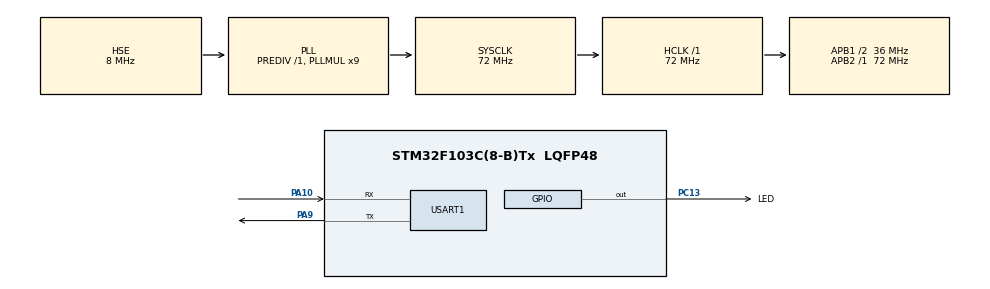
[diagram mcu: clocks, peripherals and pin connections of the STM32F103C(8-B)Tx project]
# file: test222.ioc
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Dma.Request0=USART1_TX
Dma.Request1=USART1_RX
Dma.USART1_RX.1.Direction=DMA_PERIPH_TO_MEMORY
Dma.USART1_RX.1.Instance=DMA1_Channel5
Dma.USART1_RX.1.MemDataAlignment=DMA_MDATAALIGN_BYTE
Dma.USART1_RX.1.MemInc=DMA_MINC_ENABLE
Dma.USART1_RX.1.Mode=DMA_NORMAL
Dma.USART1_RX.1.PeriphDataAlignment=DMA_PDATAALIGN_BYTE
Dma.USART1_RX.1.PeriphInc=DMA_PINC_DISABLE
Dma.USART1_RX.1.Priority=DMA_PRIORITY_LOW
Dma.USART1_TX.0.Direction=DMA_MEMORY_TO_PERIPH
Dma.USART1_TX.0.Instance=DMA1_Channel4
Dma.USART1_TX.0.MemDataAlignment=DMA_MDATAALIGN_BYTE
Dma.USART1_TX.0.MemInc=DMA_MINC_ENABLE
Dma.USART1_TX.0.Mode=DMA_NORMAL
Dma.USART1_TX.0.PeriphDataAlignment=DMA_PDATAALIGN_BYTE
Dma.USART1_TX.0.PeriphInc=DMA_PINC_DISABLE
Dma.USART1_TX.0.Priority=DMA_PRIORITY_LOW
FREERTOS.Tasks01=defaultTask,0,128,StartDefaultTask,Default,NULL,Dynamic,NULL,NULL;myTask02,-3,128,StartTask02,Default,NULL,Dynamic,NULL,NULL
Mcu.Family=STM32F1
Mcu.Name=STM32F103C(8-B)Tx
Mcu.Package=LQFP48
NVIC.DMA1_Channel4_IRQn=true\:5\:0\:false\:false\:true\:true\:false\:true
NVIC.DMA1_Channel5_IRQn=true\:5\:0\:false\:false\:true\:true\:false\:true
NVIC.PriorityGroup=NVIC_PRIORITYGROUP_4
NVIC.TIM1_UP_IRQn=true\:0\:0\:false\:false\:true\:false\:false\:true
NVIC.TimeBase=TIM1_UP_IRQn
NVIC.TimeBaseIP=TIM1
NVIC.USART1_IRQn=true\:5\:0\:false\:false\:true\:true\:true\:true
PA10.Mode=Asynchronous
PA10.Signal=USART1_RX
PA13.Mode=Trace_Asynchronous_SW
PA13.Signal=SYS_JTMS-SWDIO
PA14.Mode=Trace_Asynchronous_SW
PA14.Signal=SYS_JTCK-SWCLK
PA9.Mode=Asynchronous
PA9.Signal=USART1_TX
PB3.Mode=Trace_Asynchronous_SW
PB3.Signal=SYS_JTDO-TRACESWO
PC13-TAMPER-RTC.GPIO_Label=LED
PC13-TAMPER-RTC.Signal=GPIO_Output
PC14-OSC32_IN.Mode=LSE-External-Oscillator
PC14-OSC32_IN.Signal=RCC_OSC32_IN
PC15-OSC32_OUT.Mode=LSE-External-Oscillator
PC15-OSC32_OUT.Signal=RCC_OSC32_OUT
PD0-OSC_IN.Mode=HSE-External-Oscillator
PD0-OSC_IN.Signal=RCC_OSC_IN
PD1-OSC_OUT.Mode=HSE-External-Oscillator
PD1-OSC_OUT.Signal=RCC_OSC_OUT
ProjectManager.HeapSize=0x200
ProjectManager.StackSize=0x400
ProjectManager.TargetToolchain=MDK-ARM V5
RCC.AHBFreq_Value=72000000
RCC.APB1CLKDivider=RCC_HCLK_DIV2
RCC.APB1Freq_Value=36000000
RCC.APB1TimFreq_Value=72000000
RCC.APB2Freq_Value=72000000
RCC.APB2TimFreq_Value=72000000
RCC.HCLKFreq_Value=72000000
RCC.PLLMUL=RCC_PLL_MUL9
RCC.PLLSourceVirtual=RCC_PLLSOURCE_HSE
RCC.SYSCLKFreq_VALUE=72000000
RCC.SYSCLKSource=RCC_SYSCLKSOURCE_PLLCLK
RCC.USBFreq_Value=72000000
USART1.VirtualMode=VM_ASYNC
VP_FREERTOS_VS_CMSIS_V1.Mode=CMSIS_V1
VP_SYS_VS_tim1.Mode=TIM1
board=custom

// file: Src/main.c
/* USER CODE BEGIN Header */
/**
  ******************************************************************************
  * @file           : main.c
  * @brief          : Main program body
  ******************************************************************************
  * @attention
  *
  * <h2><center>&copy; Copyright (c) 2020 STMicroelectronics.
  * All rights reserved.</center></h2>
  *
  * This software component is licensed by ST under BSD 3-Clause license,
  * the "License"; You may not use this file except in compliance with the
  * License. You may obtain a copy of the License at:
  *                        opensource.org/licenses/BSD-3-Clause
  *
  ******************************************************************************
  */
/* USER CODE END Header */
#include "main.h"
#include "cmsis_os.h"
#include "dma.h"
#include "usart.h"
#include "gpio.h"

/* USER CODE BEGIN Includes */
#include "sim808.h"
#include "stdio.h"
#include "string.h"
/* USER CODE END Includes */

/* USER CODE BEGIN PTD */
	extern uint8_t str_GSM[GSM_BUFF_SIZE];
/* USER CODE END PTD */

void SystemClock_Config(void);
void MX_FREERTOS_Init(void);

int main(void)
{

  /* MCU Configuration--------------------------------------------------------*/

  /* Reset of all peripherals, Initializes the Flash interface and the Systick. */
  HAL_Init();

  /* Configure the system clock */
  SystemClock_Config();

  /* Initialize all configured peripherals */
  MX_GPIO_Init();
  MX_DMA_Init();
  MX_USART1_UART_Init();
  /* USER CODE BEGIN 2 */

	printf("OK printf ready>>>\r\n");
  /* USER CODE END 2 */

  /* Call init function for freertos objects (in freertos.c) */
  MX_FREERTOS_Init();
  /* Start scheduler */
  osKernelStart();

  /* We should never get here as control is now taken by the scheduler */
  /* Infinite loop */
  while (1)
  {

  }
}

void SystemClock_Config(void)
{
  RCC_OscInitTypeDef RCC_OscInitStruct = {0};
  RCC_ClkInitTypeDef RCC_ClkInitStruct = {0};

  /** Initializes the RCC Oscillators according to the specified parameters
  * in the RCC_OscInitTypeDef structure.
  */
  RCC_OscInitStruct.OscillatorType = RCC_OSCILLATORTYPE_HSE;
  RCC_OscInitStruct.HSEState = RCC_HSE_ON;
  RCC_OscInitStruct.HSEPredivValue = RCC_HSE_PREDIV_DIV1;
  RCC_OscInitStruct.HSIState = RCC_HSI_ON;
  RCC_OscInitStruct.PLL.PLLState = RCC_PLL_ON;
  RCC_OscInitStruct.PLL.PLLSource = RCC_PLLSOURCE_HSE;
  RCC_OscInitStruct.PLL.PLLMUL = RCC_PLL_MUL9;
  if (HAL_RCC_OscConfig(&RCC_OscInitStruct) != HAL_OK)
  {
    Error_Handler();
  }
  /** Initializes the CPU, AHB and APB buses clocks
  */
  RCC_ClkInitStruct.ClockType = RCC_CLOCKTYPE_HCLK|RCC_CLOCKTYPE_SYSCLK
                              |RCC_CLOCKTYPE_PCLK1|RCC_CLOCKTYPE_PCLK2;
  RCC_ClkInitStruct.SYSCLKSource = RCC_SYSCLKSOURCE_PLLCLK;
  RCC_ClkInitStruct.AHBCLKDivider = RCC_SYSCLK_DIV1;
  RCC_ClkInitStruct.APB1CLKDivider = RCC_HCLK_DIV2;
  RCC_ClkInitStruct.APB2CLKDivider = RCC_HCLK_DIV1;

  if (HAL_RCC_ClockConfig(&RCC_ClkInitStruct, FLASH_LATENCY_2) != HAL_OK)
  {
    Error_Handler();
  }
}

void HAL_TIM_PeriodElapsedCallback(TIM_HandleTypeDef *htim)
{
  if (htim->Instance == TIM1) {
    HAL_IncTick();
  }
}

void Error_Handler(void)
{
}

/************************ (C) COPYRIGHT STMicroelectronics *****END OF FILE****/

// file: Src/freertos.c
/* USER CODE BEGIN Header */
/**
  ******************************************************************************
  * File Name          : freertos.c
  * Description        : Code for freertos applications
  ******************************************************************************
  * @attention
  *
  * <h2><center>&copy; Copyright (c) 2020 STMicroelectronics.
  * All rights reserved.</center></h2>
  *
  * This software component is licensed by ST under Ultimate Liberty license
  * SLA0044, the "License"; You may not use this file except in compliance with
  * the License. You may obtain a copy of the License at:
  *                             www.st.com/SLA0044
  *
  ******************************************************************************
  */
/* USER CODE END Header */

#include "FreeRTOS.h"
#include "task.h"
#include "main.h"
#include "cmsis_os.h"

/* USER CODE BEGIN Includes */
	#include "stdio.h"
	#include "string.h"
	#include "sim808.h"

	extern UART_HandleTypeDef huart1;
	extern char str_GSM[1024];

	extern uint8_t flag_RDY;
	extern uint8_t flag_call;
	extern uint8_t flag_sms;
/* USER CODE END Includes */

osThreadId defaultTaskHandle;
osThreadId myTask02Handle;

void StartDefaultTask(void const * argument);
void StartTask02(void const * argument);

void MX_FREERTOS_Init(void); /* (MISRA C 2004 rule 8.1) */

/* GetIdleTaskMemory prototype (linked to static allocation support) */
void vApplicationGetIdleTaskMemory( StaticTask_t **ppxIdleTaskTCBBuffer, StackType_t **ppxIdleTaskStackBuffer, uint32_t *pulIdleTaskStackSize );

/* USER CODE BEGIN GET_IDLE_TASK_MEMORY */
static StaticTask_t xIdleTaskTCBBuffer;
static StackType_t xIdleStack[configMINIMAL_STACK_SIZE];

void vApplicationGetIdleTaskMemory( StaticTask_t **ppxIdleTaskTCBBuffer, StackType_t **ppxIdleTaskStackBuffer, uint32_t *pulIdleTaskStackSize )
{
  *ppxIdleTaskTCBBuffer = &xIdleTaskTCBBuffer;
  *ppxIdleTaskStackBuffer = &xIdleStack[0];
  *pulIdleTaskStackSize = configMINIMAL_STACK_SIZE;
  /* place for user code */
}
/* USER CODE END GET_IDLE_TASK_MEMORY */

void MX_FREERTOS_Init(void) {

  /* Create the thread(s) */
  /* definition and creation of defaultTask */
  osThreadDef(defaultTask, StartDefaultTask, osPriorityNormal, 0, 128);
  defaultTaskHandle = osThreadCreate(osThread(defaultTask), NULL);

  /* definition and creation of myTask02 */
  osThreadDef(myTask02, StartTask02, osPriorityIdle, 0, 128);
  myTask02Handle = osThreadCreate(osThread(myTask02), NULL);

}

void StartDefaultTask(void const * argument)
{
  /* USER CODE BEGIN StartDefaultTask */
	printf("OK StartDefaultTask>>>\r\n");

	GSM_restart_recive();
	printf("Waiting for GSM to send RDY...\r\n");

//	osDelay(500);
//	GSM_init();
  /* Infinite loop */
  for(;;)
  {
		if(flag_RDY == 1 && flag_call == 1 && flag_sms == 1)
		{
			flag_RDY = 0;
			flag_call =0;
			flag_sms = 0;
			GSM_init();
		}
		GSM_callback();
		osDelay(1);

  }
  /* USER CODE END StartDefaultTask */
}

void StartTask02(void const * argument)
{
  /* USER CODE BEGIN StartTask02 */
	printf("OK StartTask02>>>\r\n");
  /* Infinite loop */
  for(;;)
  {
		HAL_GPIO_TogglePin(LED_GPIO_Port,LED_Pin);
    osDelay(100);
  }
  /* USER CODE END StartTask02 */
}

/************************ (C) COPYRIGHT STMicroelectronics *****END OF FILE****/
